# SAMA7G54D2G device description
Architecture: CORTEX-A7; Family: SAMA; Series: SAMA7G
Registers are 32-bit, read-write, reset 0x0 unless marked. A register's access mark holds for its fields unless they carry their own. Offsets are from the block's base; [hi:lo] are bit positions; {n}, {i} and the like mark numbered series; 'fields as' and 'values as' point back to an identical list.

## RTT — Real-time Timer
Instances: RTT 0xE001D020
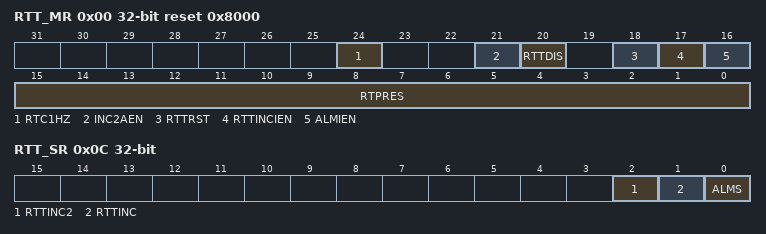
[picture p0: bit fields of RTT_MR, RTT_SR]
0x00 RTT_MR reset 0x8000 — Mode Register
  [24] RTC1HZ — Real-Time Clock 1Hz Clock Selection
    0=The RTT 32-bit counter is driven by the 16-bit prescaler roll-over events; 1=The RTT 32-bit counter is driven by the 1Hz RTC clock
  [21] INC2AEN — RTTINC2 Alarm and Interrupt Enable
    0=The RTTINC2 flag is not a source of the RTT alarm signal nor a source of interrupt; 1=The RTTINC2 flag is a source of the RTT alarm signal and a source of interrupt
  [20] RTTDIS — Real-time Timer Disable
    0=The real-time timer is enabled; 1=The real-time timer is disabled (no dynamic power consumption)
  [18] RTTRST — Real-time Timer Restart
    0=No effect; 1=Reloads and restarts the clock divider with the new programmed value. This also resets the 32-bit counter.
  [17] RTTINCIEN — Real-time Timer Increment Interrupt Enable
    0=The bit RTTINC in RTT_SR has no effect on interrupt; 1=The bit RTTINC in RTT_SR asserts interrupt
  [16] ALMIEN — Alarm Interrupt Enable
    0=The bit ALMS in RTT_SR has no effect on interrupt; 1=The bit ALMS in RTT_SR asserts interrupt
  [15:0] RTPRES — Real-time Timer Prescaler Value
0x04 RTT_AR reset 0xFFFFFFFF — Alarm Register
  [31:0] ALMV — Alarm Value
0x08 RTT_VR ro — Value Register
  [31:0] CRTV — Current Real-time Value
0x0C RTT_SR ro — Status Register
  [2] RTTINC2 — Predefined Number of Prescaler Roll-overs Status (cleared on read)
    0=SELINC2=0 or the number of prescaler roll-overs programmed through the SELINC2 field in RTT_MODR has not been reached since the last read of the RTT_SR; 1=The number of prescaler roll-overs programmed through the SELINC2 field has been reached since the last read of the RTT_SR
  [1] RTTINC — Prescaler Roll-over Status (cleared on read)
    0=No prescaler roll-over occurred since the last read of the RTT_SR; 1=Prescaler roll-over occurred since the last read of the RTT_SR
  [0] ALMS — Real-time Alarm Status (cleared on read)
    0=The Real-time Alarm has not occurred since the last read of RTT_SR; 1=The Real-time Alarm occurred since the last read of RTT_SR
0x10 RTT_MODR — Modulo Selection Register
  [2:0] SELINC2 — Selection of the 32-bit Counter Modulo to generate RTTINC2 Flag
    0=NO_RTTINC2 (The RTTINC2 flag never rises); 1=MOD64 (The RTTINC2 flag is set when CRTV modulo 64 equals 0); 2=MOD128 (The RTTINC2 flag is set when CRTV modulo 128 equals 0); 3=MOD256 (The RTTINC2 flag is set when CRTV modulo 256 equals 0); 4=MOD512 (The RTTINC2 flag is set when CRTV modulo 512 equals 0); 5=MOD1024 (The RTTINC2 flag is set when CRTV modulo 1024 equals 0. Example: If RTPRES=32 then RTTINC2 flag rises once per second if the slow clock is 32.768 kHz.); 6=MOD2048 (The RTTINC2 flag is set when CRTV modulo 2048 equals 0); 7=MOD4096 (The RTTINC2 flag is set when CRTV modulo 4096 equals 0)
0x14 RTT_TSR ro — TimeStamp Register
  [23:0] TSTAMP — Real-time Timer Value Timestamp

## SCKC — Slow Clock Controller
Instances: SCKC 0xE001D050
0x00 SCKC_CR reset 0x1 — Slow Clock Controller Configuration Register
  [24] TD_OSCSEL — Timing Domain Slow Clock Selector
    0=RC (Slow clock of the timing domain is driven by the embedded 32 kHz (typical) RC oscillator.); 1=XTAL (Slow clock of the timing domain is driven by the 32.768 kHz crystal oscillator.)

## SFR — Special Function Register
Instances: SFR 0xE1624000
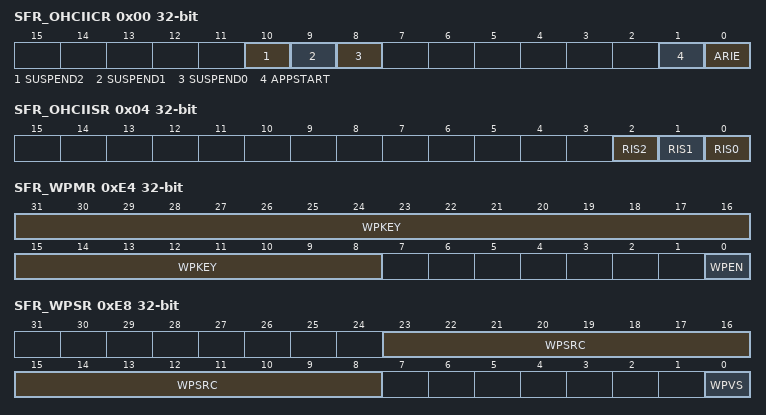
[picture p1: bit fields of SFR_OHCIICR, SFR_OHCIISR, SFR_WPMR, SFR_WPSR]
0x00 SFR_OHCIICR — OHCI Interrupt Configuration Register
  [10] SUSPEND2 — USB PORT 2
    0=Suspends controlled by EHCI-OCHI; 1=Forces the suspend for PORTx
  [9] SUSPEND1 — USB PORT 1
    values as SUSPEND2
  [8] SUSPEND0 — USB PORT 0
    values as SUSPEND2
  [1] APPSTART — Reserved
  [0] ARIE — OHCI Asynchronous Resume Interrupt Enable
    0=Interrupt is disabled; 1=Interrupt is enabled
0x04 SFR_OHCIISR ro — OHCI Interrupt Status Register
  [all] fields
    0=OHCI port resume not detected; 1=OHCI port resume detected
  [2] RIS2 — OHCI Resume Interrupt Status Port 2
  [1] RIS1 — OHCI Resume Interrupt Status Port 1
  [0] RIS0 — OHCI Resume Interrupt Status Port 0
0xE4 SFR_WPMR — Write Protection Mode Register
  [31:8] WPKEY — Write Protection Key
    0x534652=PASSWD (Writing any other value in this field aborts the write operation of the WPEN bit. Always reads as 0.)
  [0] WPEN — Write Protection Enable
    0=Disables the write protection if WPKEY value corresponds to 0x534652 ("SFR" in ASCII); 1=Enables the write protection if WPKEY value corresponds to 0x534652 ("SFR" in ASCII)
0xE8 SFR_WPSR ro — Write Protection Status Register
  [23:8] WPSRC — Write Protection Source
  [0] WPVS — Write Protection Violation Status
    0=No write protection violation has occurred since the last read of SFR_WPSR; 1=A write protection violation has occurred since the last read of SFR_WPSR. If this violation is an unauthorized attempt to write a protected register, the associated violation is reported into field WPSRC.
0x200C SFR_DEBUG — Debug Register
  [0] PROT — Protection Debug
    0=Protection debug is disabled; 1=Protection debug is enabled
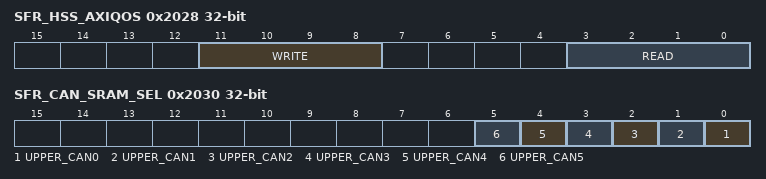
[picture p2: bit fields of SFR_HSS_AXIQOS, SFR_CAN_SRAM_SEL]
0x2028 SFR_HSS_AXIQOS — HSS AXI QOS Register
  [11:8] WRITE — QOS value for write transfer from HSS to the DDR controller
  [3:0] READ — QOS value for read transfer from HSS to the DDR controller
0x202C SFR_UDDRC — UDDRC Register
  [0] DIS_DECERR — Disable Decode Error
    0=Enables decode error when reading a non-existing register in the DDR controller Configuration Address Space; 1=Disables decode error when reading a non-existing register in the DDR controller Configuration Address Space
0x2030 SFR_CAN_SRAM_SEL — SFR CAN SRAM Selection Register
  [all] fields
    0=CANx accesses the lower 64K SRAM; 1=CANx accesses the upper 64K SRAM
  [n] UPPER_CAN{n} (n=0..5) — CANx Upper 64K SRAM Selection
